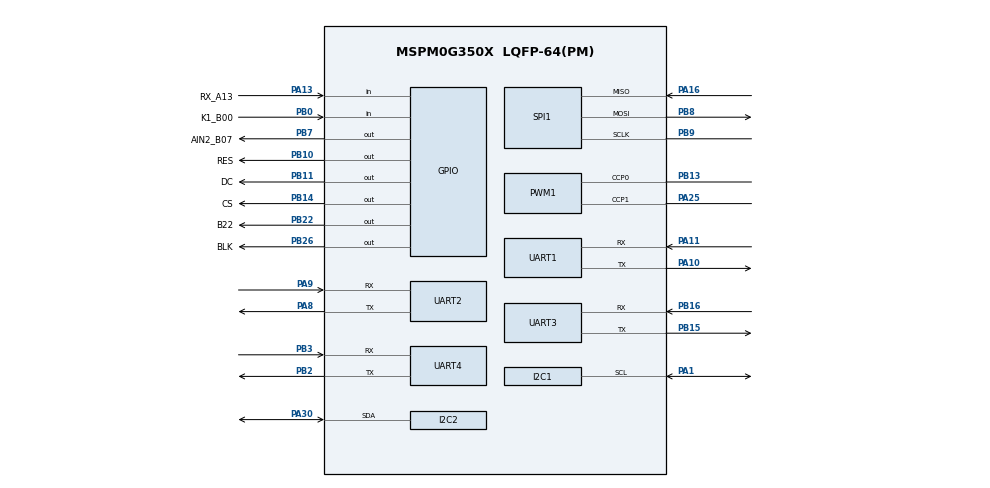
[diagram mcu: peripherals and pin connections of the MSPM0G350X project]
/**
 * @cliArgs --device "MSPM0G350X" --part "Default" --package "LQFP-64(PM)" --product "mspm0_sdk@2.10.00.04"
 * @versions {"tool":"1.26.2+4477"}
 */

/**
 * Import the modules used in this configuration.
 */
const ADC12   = scripting.addModule("/ti/driverlib/ADC12", {}, false);
const ADC121  = ADC12.addInstance();
const ADC122  = ADC12.addInstance();
const Board   = scripting.addModule("/ti/driverlib/Board");
const GPIO    = scripting.addModule("/ti/driverlib/GPIO", {}, false);
const GPIO1   = GPIO.addInstance();
const GPIO2   = GPIO.addInstance();
const GPIO3   = GPIO.addInstance();
const GPIO4   = GPIO.addInstance();
const GPIO5   = GPIO.addInstance();
const GPIO6   = GPIO.addInstance();
const GPIO7   = GPIO.addInstance();
const GPIO8   = GPIO.addInstance();
const GPIO9   = GPIO.addInstance();
const GPIO10  = GPIO.addInstance();
const I2C     = scripting.addModule("/ti/driverlib/I2C", {}, false);
const I2C1    = I2C.addInstance();
const I2C2    = I2C.addInstance();
const PWM     = scripting.addModule("/ti/driverlib/PWM", {}, false);
const PWM1    = PWM.addInstance();
const SPI     = scripting.addModule("/ti/driverlib/SPI", {}, false);
const SPI1    = SPI.addInstance();
const SYSCTL  = scripting.addModule("/ti/driverlib/SYSCTL");
const SYSTICK = scripting.addModule("/ti/driverlib/SYSTICK");
const TIMER   = scripting.addModule("/ti/driverlib/TIMER", {}, false);
const TIMER1  = TIMER.addInstance();
const TIMER2  = TIMER.addInstance();
const TIMER3  = TIMER.addInstance();
const UART    = scripting.addModule("/ti/driverlib/UART", {}, false);
const UART1   = UART.addInstance();
const UART2   = UART.addInstance();
const UART3   = UART.addInstance();
const UART4   = UART.addInstance();

/**
 * Write custom configuration values to the imported modules.
 */
const divider7       = system.clockTree["PLL_PDIV"];
divider7.divideValue = 2;

const divider9       = system.clockTree["UDIV"];
divider9.divideValue = 2;

const multiplier2         = system.clockTree["PLL_QDIV"];
multiplier2.multiplyValue = 5;

const mux4       = system.clockTree["EXHFMUX"];
mux4.inputSelect = "EXHFMUX_XTAL";

const mux5       = system.clockTree["EXLFMUX"];
mux5.inputSelect = "EXLFMUX_XTAL";

const mux8       = system.clockTree["HSCLKMUX"];
mux8.inputSelect = "HSCLKMUX_SYSPLL2X";

ADC121.$name                             = "ADC_A15";
ADC121.peripheral.adcPin0.$assign        = "PA15";
ADC121.adcPin0Config.hideOutputInversion = scripting.forceWrite(false);
ADC121.adcPin0Config.$name               = "ti_driverlib_gpio_GPIOPinGeneric15";

ADC122.sampClkDiv                        = "DL_ADC12_CLOCK_DIVIDE_8";
ADC122.repeatMode                        = true;
ADC122.sampleTime0                       = "2us";
ADC122.sampClkSrc                        = "DL_ADC12_CLOCK_ULPCLK";
ADC122.$name                             = "huidu";
ADC122.adcMem0_name                      = "1_A27";
ADC122.configureDMA                      = true;
ADC122.sampCnt                           = 1;
ADC122.enabledDMATriggers                = ["DL_ADC12_DMA_MEM0_RESULT_LOADED"];
ADC122.peripheral.$assign                = "ADC0";
ADC122.peripheral.adcPin0.$assign        = "PA27";
ADC122.adcPin0Config.hideOutputInversion = scripting.forceWrite(false);
ADC122.adcPin0Config.$name               = "ti_driverlib_gpio_GPIOPinGeneric16";
ADC122.DMA_CHANNEL.$name                 = "DMA_CH0";
ADC122.DMA_CHANNEL.srcLength             = "HALF_WORD";
ADC122.DMA_CHANNEL.dstLength             = "HALF_WORD";
ADC122.DMA_CHANNEL.configureTransferSize = true;
ADC122.DMA_CHANNEL.transferSize          = 40;
ADC122.DMA_CHANNEL.transferMode          = "FULL_CH_REPEAT_SINGLE";


GPIO1.$name                         = "LCD";
GPIO1.port                          = "PORTB";
GPIO1.associatedPins.create(4);
GPIO1.associatedPins[0].$name       = "RES";
GPIO1.associatedPins[0].ioStructure = "SD";
GPIO1.associatedPins[0].assignedPin = "10";
GPIO1.associatedPins[0].pin.$assign = "PB10";
GPIO1.associatedPins[1].ioStructure = "SD";
GPIO1.associatedPins[1].$name       = "DC";
GPIO1.associatedPins[1].assignedPin = "11";
GPIO1.associatedPins[1].pin.$assign = "PB11";
GPIO1.associatedPins[2].ioStructure = "SD";
GPIO1.associatedPins[2].$name       = "CS";
GPIO1.associatedPins[2].assignedPin = "14";
GPIO1.associatedPins[2].pin.$assign = "PB14";
GPIO1.associatedPins[3].ioStructure = "SD";
GPIO1.associatedPins[3].$name       = "BLK";
GPIO1.associatedPins[3].assignedPin = "26";
GPIO1.associatedPins[3].pin.$assign = "PB26";

GPIO2.$name                          = "bianma1";
GPIO2.associatedPins.create(2);
GPIO2.associatedPins[0].assignedPort = "PORTA";
GPIO2.associatedPins[0].assignedPin  = "28";
GPIO2.associatedPins[0].$name        = "read_A28";
GPIO2.associatedPins[0].direction    = "INPUT";
GPIO2.associatedPins[1].assignedPort = "PORTA";
GPIO2.associatedPins[1].assignedPin  = "31";
GPIO2.associatedPins[1].$name        = "read_A31";

GPIO3.$name                          = "bianma2";
GPIO3.associatedPins.create(2);
GPIO3.associatedPins[0].assignedPort = "PORTB";
GPIO3.associatedPins[0].assignedPin  = "04";
GPIO3.associatedPins[0].$name        = "read_B04";
GPIO3.associatedPins[0].direction    = "INPUT";
GPIO3.associatedPins[1].assignedPort = "PORTB";
GPIO3.associatedPins[1].assignedPin  = "05";
GPIO3.associatedPins[1].$name        = "read_B05";

GPIO4.$name                         = "TB6612";
GPIO4.associatedPins.create(4);
GPIO4.associatedPins[0].$name       = "AIN1_B06";
GPIO4.associatedPins[1].$name       = "AIN2_B07";
GPIO4.associatedPins[1].pin.$assign = "PB7";
GPIO4.associatedPins[2].$name       = "BIN1_B23";
GPIO4.associatedPins[3].$name       = "BIN2_B27";

GPIO5.$name                   = "BEEP";
GPIO5.associatedPins[0].$name = "A29";

GPIO6.$name                         = "chaosheng";
GPIO6.associatedPins.create(2);
GPIO6.associatedPins[0].$name       = "Trig_B17";
GPIO6.associatedPins[0].ioStructure = "SD";
GPIO6.associatedPins[1].$name       = "Echo_B18";
GPIO6.associatedPins[1].direction   = "INPUT";
GPIO6.associatedPins[1].ioStructure = "SD";

GPIO7.$name                       = "ghuidu";
GPIO7.associatedPins.create(8);
GPIO7.associatedPins[0].$name     = "B25_2";
GPIO7.associatedPins[0].direction = "INPUT";
GPIO7.associatedPins[1].$name     = "A24_4";
GPIO7.associatedPins[1].direction = "INPUT";
GPIO7.associatedPins[2].$name     = "B19_3";
GPIO7.associatedPins[2].direction = "INPUT";
GPIO7.associatedPins[3].$name     = "A14_6";
GPIO7.associatedPins[3].direction = "INPUT";
GPIO7.associatedPins[4].$name     = "A27_1";
GPIO7.associatedPins[4].direction = "INPUT";
GPIO7.associatedPins[5].$name     = "A26_5";
GPIO7.associatedPins[5].direction = "INPUT";
GPIO7.associatedPins[6].$name     = "A07_7";
GPIO7.associatedPins[6].direction = "INPUT";
GPIO7.associatedPins[7].$name     = "B12_8";
GPIO7.associatedPins[7].direction = "INPUT";

GPIO8.$name                              = "key";
GPIO8.associatedPins.create(5);
GPIO8.associatedPins[0].$name            = "K1_B00";
GPIO8.associatedPins[0].direction        = "INPUT";
GPIO8.associatedPins[0].assignedPin      = "00";
GPIO8.associatedPins[0].assignedPort     = "PORTB";
GPIO8.associatedPins[0].pin.$assign      = "PB0";
GPIO8.associatedPins[1].$name            = "K4_B24";
GPIO8.associatedPins[1].direction        = "INPUT";
GPIO8.associatedPins[1].assignedPort     = "PORTB";
GPIO8.associatedPins[1].assignedPin      = "24";
GPIO8.associatedPins[2].direction        = "INPUT";
GPIO8.associatedPins[2].$name            = "K3_A22";
GPIO8.associatedPins[2].assignedPort     = "PORTA";
GPIO8.associatedPins[2].assignedPin      = "22";
GPIO8.associatedPins[3].assignedPort     = "PORTB";
GPIO8.associatedPins[3].assignedPin      = "01";
GPIO8.associatedPins[3].$name            = "K2B_01";
GPIO8.associatedPins[3].direction        = "INPUT";
GPIO8.associatedPins[4].$name            = "USE_key_B21";
GPIO8.associatedPins[4].direction        = "INPUT";
GPIO8.associatedPins[4].assignedPort     = "PORTB";
GPIO8.associatedPins[4].assignedPin      = "21";
GPIO8.associatedPins[4].internalResistor = "PULL_UP";

GPIO9.$name                         = "LED";
GPIO9.associatedPins[0].$name       = "B22";
GPIO9.associatedPins[0].pin.$assign = "PB22";

GPIO10.$name                         = "can";
GPIO10.associatedPins.create(2);
GPIO10.associatedPins[0].$name       = "TX_A12";
GPIO10.associatedPins[1].$name       = "RX_A13";
GPIO10.associatedPins[1].direction   = "INPUT";
GPIO10.associatedPins[1].pin.$assign = "PA13";

I2C1.$name                                   = "MPU9250";
I2C1.basicEnableController                   = true;
I2C1.basicControllerStandardBusSpeed         = "Fast";
I2C1.peripheral.$assign                      = "I2C0";
I2C1.peripheral.sdaPin.$assignAllowConflicts = "PA0";
I2C1.peripheral.sclPin.$assign               = "PA1";
I2C1.sdaPinConfig.hideOutputInversion        = scripting.forceWrite(false);
I2C1.sdaPinConfig.onlyInternalResistor       = scripting.forceWrite(false);
I2C1.sdaPinConfig.passedPeripheralType       = scripting.forceWrite("Digital");
I2C1.sdaPinConfig.$name                      = "ti_driverlib_gpio_GPIOPinGeneric11";
I2C1.sclPinConfig.hideOutputInversion        = scripting.forceWrite(false);
I2C1.sclPinConfig.onlyInternalResistor       = scripting.forceWrite(false);
I2C1.sclPinConfig.passedPeripheralType       = scripting.forceWrite("Digital");
I2C1.sclPinConfig.$name                      = "ti_driverlib_gpio_GPIOPinGeneric12";

I2C2.$name                     = "I2C_1";
I2C2.peripheral.sdaPin.$assign = "PA30";
I2C2.sdaPinConfig.$name        = "ti_driverlib_gpio_GPIOPinGeneric13";
I2C2.sclPinConfig.$name        = "ti_driverlib_gpio_GPIOPinGeneric14";

PWM1.$name                              = "TB6612_PWM";
PWM1.clockDivider                       = 2;
PWM1.timerCount                         = 2000;
PWM1.timerStartTimer                    = true;
PWM1.peripheral.$assign                 = "TIMG12";
PWM1.peripheral.ccp0Pin.$assign         = "PB13";
PWM1.peripheral.ccp1Pin.$assign         = "PA25";
PWM1.PWM_CHANNEL_0.$name                = "ti_driverlib_pwm_PWMTimerCC0";
PWM1.PWM_CHANNEL_1.$name                = "ti_driverlib_pwm_PWMTimerCC1";
PWM1.ccp0PinConfig.direction            = scripting.forceWrite("OUTPUT");
PWM1.ccp0PinConfig.hideOutputInversion  = scripting.forceWrite(false);
PWM1.ccp0PinConfig.onlyInternalResistor = scripting.forceWrite(false);
PWM1.ccp0PinConfig.passedPeripheralType = scripting.forceWrite("Digital");
PWM1.ccp0PinConfig.$name                = "ti_driverlib_gpio_GPIOPinGeneric17";
PWM1.ccp1PinConfig.direction            = scripting.forceWrite("OUTPUT");
PWM1.ccp1PinConfig.hideOutputInversion  = scripting.forceWrite(false);
PWM1.ccp1PinConfig.onlyInternalResistor = scripting.forceWrite(false);
PWM1.ccp1PinConfig.passedPeripheralType = scripting.forceWrite("Digital");
PWM1.ccp1PinConfig.$name                = "ti_driverlib_gpio_GPIOPinGeneric18";

SPI1.$name                              = "SPI_LCD";
SPI1.frameFormat                        = "MOTO3";
SPI1.rxFifoThreshold                    = "DL_SPI_RX_FIFO_LEVEL_ONE_FRAME";
SPI1.targetBitRate                      = 2000000;
SPI1.txFifoThreshold                    = "DL_SPI_TX_FIFO_LEVEL_3_4_EMPTY";
SPI1.sclkPinConfig.direction            = scripting.forceWrite("OUTPUT");
SPI1.sclkPinConfig.onlyInternalResistor = scripting.forceWrite(false);
SPI1.sclkPinConfig.passedPeripheralType = scripting.forceWrite("Digital");
SPI1.sclkPinConfig.$name                = "ti_driverlib_gpio_GPIOPinGeneric0";
SPI1.mosiPinConfig.direction            = scripting.forceWrite("OUTPUT");
SPI1.mosiPinConfig.hideOutputInversion  = scripting.forceWrite(false);
SPI1.mosiPinConfig.onlyInternalResistor = scripting.forceWrite(false);
SPI1.mosiPinConfig.passedPeripheralType = scripting.forceWrite("Digital");
SPI1.mosiPinConfig.$name                = "ti_driverlib_gpio_GPIOPinGeneric1";
SPI1.misoPinConfig.onlyInternalResistor = scripting.forceWrite(false);
SPI1.misoPinConfig.passedPeripheralType = scripting.forceWrite("Digital");
SPI1.misoPinConfig.$name                = "ti_driverlib_gpio_GPIOPinGeneric2";
SPI1.peripheral.$assign                 = "SPI1";
SPI1.peripheral.sclkPin.$assign         = "PB9";
SPI1.peripheral.mosiPin.$assign         = "PB8";
SPI1.peripheral.misoPin.$assign         = "PA16";

SYSCTL.clockTreeEn           = true;
SYSCTL.forceDefaultClkConfig = true;

SYSTICK.periodEnable    = true;
SYSTICK.interruptEnable = true;
SYSTICK.systickEnable   = true;
SYSTICK.period          = 32000;

TIMER1.$name              = "BIANMA1_TIM";
TIMER1.timerClkDiv        = 8;
TIMER1.timerClkPrescale   = 10;
TIMER1.timerMode          = "PERIODIC_UP";
TIMER1.timerPeriod        = "50 ms";
TIMER1.peripheral.$assign = "TIMG7";

TIMER2.$name              = "BIANMA2_TIM";
TIMER2.timerMode          = "PERIODIC_UP";
TIMER2.timerPeriod        = "50.00 ms";
TIMER2.timerClkDiv        = 8;
TIMER2.timerClkPrescale   = 10;
TIMER2.peripheral.$assign = "TIMA1";

TIMER3.$name              = "SYSTEM_TIIM";
TIMER3.timerClkDiv        = 8;
TIMER3.timerPeriod        = "1 ms";
TIMER3.timerStartTimer    = true;
TIMER3.peripheral.$assign = "TIMA0";

UART1.$name                    = "UART_0";
UART1.enabledInterrupts        = ["BREAK_ERROR","CTS_DONE","DMA_DONE_RX","DMA_DONE_TX","EOT_DONE","FRAMING_ERROR","NOISE_ERROR","OVERRUN_ERROR","PARITY_ERROR","RX","RXD_NEG_EDGE","RXD_POS_EDGE","RX_TIMEOUT_ERROR","TX"];
UART1.interruptPriority        = "0";
UART1.peripheral.rxPin.$assign = "PA11";
UART1.peripheral.txPin.$assign = "PA10";
UART1.txPinConfig.$name        = "ti_driverlib_gpio_GPIOPinGeneric3";
UART1.rxPinConfig.$name        = "ti_driverlib_gpio_GPIOPinGeneric4";

UART2.$name                            = "K230";
UART2.interruptPriority                = "2";
UART2.enabledInterrupts                = ["RX_TIMEOUT_ERROR"];
UART2.peripheral.$assign               = "UART1";
UART2.peripheral.rxPin.$assign         = "PA9";
UART2.peripheral.txPin.$assign         = "PA8";
UART2.txPinConfig.direction            = scripting.forceWrite("OUTPUT");
UART2.txPinConfig.hideOutputInversion  = scripting.forceWrite(false);
UART2.txPinConfig.onlyInternalResistor = scripting.forceWrite(false);
UART2.txPinConfig.passedPeripheralType = scripting.forceWrite("Digital");
UART2.txPinConfig.$name                = "ti_driverlib_gpio_GPIOPinGeneric5";
UART2.rxPinConfig.hideOutputInversion  = scripting.forceWrite(false);
UART2.rxPinConfig.onlyInternalResistor = scripting.forceWrite(false);
UART2.rxPinConfig.passedPeripheralType = scripting.forceWrite("Digital");
UART2.rxPinConfig.$name                = "ti_driverlib_gpio_GPIOPinGeneric6";

UART3.$name                            = "x_bujin";
UART3.targetBaudRate                   = 115200;
UART3.rxTimeoutValue                   = 10;
UART3.interruptPriority                = "0";
UART3.enabledInterrupts                = ["BREAK_ERROR","CTS_DONE","DMA_DONE_RX","DMA_DONE_TX","EOT_DONE","FRAMING_ERROR","NOISE_ERROR","OVERRUN_ERROR","PARITY_ERROR","RX","RXD_NEG_EDGE","RXD_POS_EDGE","RX_TIMEOUT_ERROR","TX"];
UART3.peripheral.$assign               = "UART2";
UART3.peripheral.rxPin.$assign         = "PB16";
UART3.peripheral.txPin.$assign         = "PB15";
UART3.txPinConfig.direction            = scripting.forceWrite("OUTPUT");
UART3.txPinConfig.hideOutputInversion  = scripting.forceWrite(false);
UART3.txPinConfig.onlyInternalResistor = scripting.forceWrite(false);
UART3.txPinConfig.passedPeripheralType = scripting.forceWrite("Digital");
UART3.txPinConfig.$name                = "ti_driverlib_gpio_GPIOPinGeneric7";
UART3.rxPinConfig.hideOutputInversion  = scripting.forceWrite(false);
UART3.rxPinConfig.onlyInternalResistor = scripting.forceWrite(false);
UART3.rxPinConfig.passedPeripheralType = scripting.forceWrite("Digital");
UART3.rxPinConfig.$name                = "ti_driverlib_gpio_GPIOPinGeneric8";

UART4.$name                            = "y_bujin";
UART4.rxTimeoutValue                   = 10;
UART4.targetBaudRate                   = 115200;
UART4.interruptPriority                = "1";
UART4.enabledInterrupts                = ["BREAK_ERROR","CTS_DONE","DMA_DONE_RX","DMA_DONE_TX","EOT_DONE","FRAMING_ERROR","NOISE_ERROR","OVERRUN_ERROR","PARITY_ERROR","RX","RXD_NEG_EDGE","RXD_POS_EDGE","RX_TIMEOUT_ERROR","TX"];
UART4.peripheral.rxPin.$assign         = "PB3";
UART4.peripheral.txPin.$assign         = "PB2";
UART4.txPinConfig.direction            = scripting.forceWrite("OUTPUT");
UART4.txPinConfig.hideOutputInversion  = scripting.forceWrite(false);
UART4.txPinConfig.onlyInternalResistor = scripting.forceWrite(false);
UART4.txPinConfig.passedPeripheralType = scripting.forceWrite("Digital");
UART4.txPinConfig.$name                = "ti_driverlib_gpio_GPIOPinGeneric9";
UART4.rxPinConfig.hideOutputInversion  = scripting.forceWrite(false);
UART4.rxPinConfig.onlyInternalResistor = scripting.forceWrite(false);
UART4.rxPinConfig.passedPeripheralType = scripting.forceWrite("Digital");
UART4.rxPinConfig.$name                = "ti_driverlib_gpio_GPIOPinGeneric10";

/**
 * Pinmux solution for unlocked pins/peripherals. This ensures that minor changes to the automatic solver in a future
 * version of the tool will not impact the pinmux you originally saw.  These lines can be completely deleted in order to
 * re-solve from scratch.
 */
ADC121.peripheral.$suggestSolution             = "ADC1";
ADC122.DMA_CHANNEL.peripheral.$suggestSolution = "DMA_CH0";
Board.peripheral.$suggestSolution              = "DEBUGSS";
Board.peripheral.swclkPin.$suggestSolution     = "PA20";
Board.peripheral.swdioPin.$suggestSolution     = "PA19";
GPIO2.associatedPins[0].pin.$suggestSolution   = "PA28";
GPIO2.associatedPins[1].pin.$suggestSolution   = "PA31";
GPIO3.associatedPins[0].pin.$suggestSolution   = "PB4";
GPIO3.associatedPins[1].pin.$suggestSolution   = "PB5";
GPIO4.associatedPins[0].pin.$suggestSolution   = "PA14";
GPIO4.associatedPins[2].pin.$suggestSolution   = "PA18";
GPIO4.associatedPins[3].pin.$suggestSolution   = "PB19";
GPIO5.associatedPins[0].pin.$suggestSolution   = "PA12";
GPIO6.associatedPins[0].pin.$suggestSolution   = "PB18";
GPIO6.associatedPins[1].pin.$suggestSolution   = "PB17";
GPIO7.associatedPins[0].pin.$suggestSolution   = "PA21";
GPIO7.associatedPins[1].pin.$suggestSolution   = "PB20";
GPIO7.associatedPins[2].pin.$suggestSolution   = "PB23";
GPIO7.associatedPins[3].pin.$suggestSolution   = "PA23";
GPIO7.associatedPins[4].pin.$suggestSolution   = "PA24";
GPIO7.associatedPins[5].pin.$suggestSolution   = "PB25";
GPIO7.associatedPins[6].pin.$suggestSolution   = "PB27";
GPIO7.associatedPins[7].pin.$suggestSolution   = "PA26";
GPIO8.associatedPins[1].pin.$suggestSolution   = "PB24";
GPIO8.associatedPins[2].pin.$suggestSolution   = "PA22";
GPIO8.associatedPins[3].pin.$suggestSolution   = "PB1";
GPIO8.associatedPins[4].pin.$suggestSolution   = "PB21";
GPIO10.associatedPins[0].pin.$suggestSolution  = "PA29";
I2C2.peripheral.$suggestSolution               = "I2C1";
I2C2.peripheral.sclPin.$suggestSolution        = "PA17";
UART1.peripheral.$suggestSolution              = "UART0";
UART4.peripheral.$suggestSolution              = "UART3";
